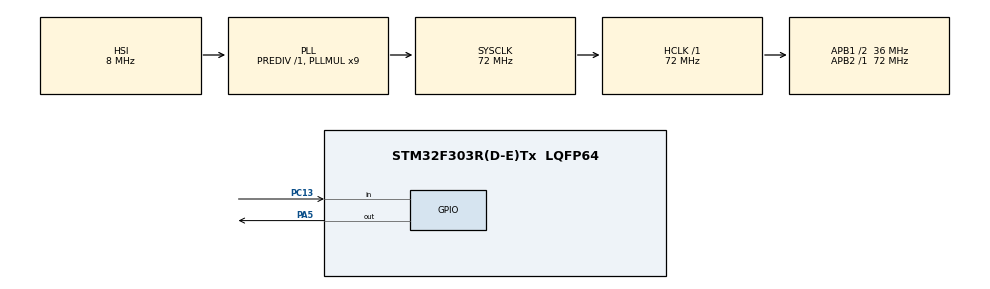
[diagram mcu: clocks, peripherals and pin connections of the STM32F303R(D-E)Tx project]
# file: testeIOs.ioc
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Mcu.Family=STM32F3
Mcu.Name=STM32F303R(D-E)Tx
Mcu.Package=LQFP64
NVIC.PriorityGroup=NVIC_PRIORITYGROUP_4
PA13.Mode=Serial_Wire
PA13.Signal=SYS_JTMS-SWDIO
PA14.Mode=Serial_Wire
PA14.Signal=SYS_JTCK-SWCLK
PA5.GPIO_Speed=GPIO_SPEED_FREQ_HIGH
PA5.PinState=GPIO_PIN_RESET
PA5.Signal=GPIO_Output
PC13.GPIO_PuPd=GPIO_PULLUP
PC13.Signal=GPIO_Input
PF0-OSC_IN.Mode=HSE-External-Oscillator
PF0-OSC_IN.Signal=RCC_OSC_IN
PF1-OSC_OUT.Mode=HSE-External-Oscillator
PF1-OSC_OUT.Signal=RCC_OSC_OUT
ProjectManager.HeapSize=0x200
ProjectManager.StackSize=0x400
ProjectManager.TargetToolchain=STM32CubeIDE
RCC.AHBFreq_Value=72000000
RCC.APB1CLKDivider=RCC_HCLK_DIV2
RCC.APB1Freq_Value=36000000
RCC.APB1TimFreq_Value=72000000
RCC.APB2Freq_Value=72000000
RCC.APB2TimFreq_Value=72000000
RCC.CortexFreq_Value=72000000
RCC.HCLKFreq_Value=72000000
RCC.HSE_VALUE=8000000
RCC.HSI_VALUE=8000000
RCC.PLLMUL=RCC_PLL_MUL9
RCC.SYSCLKFreq_VALUE=72000000
RCC.SYSCLKSourceVirtual=RCC_SYSCLKSOURCE_PLLCLK
RCC.USBFreq_Value=72000000
board=custom

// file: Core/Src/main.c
/* USER CODE BEGIN Header */
/**
  ******************************************************************************
  * @file           : main.c
  * @brief          : Main program body
  ******************************************************************************
  * @attention
  *
  * Copyright (c) 2023 STMicroelectronics.
  * All rights reserved.
  *
  * This software is licensed under terms that can be found in the LICENSE file
  * in the root directory of this software component.
  * If no LICENSE file comes with this software, it is provided AS-IS.
  *
  ******************************************************************************
  */
/* USER CODE END Header */
#include "main.h"

/* USER CODE BEGIN Includes */
#include "teste_IO.h"
/* USER CODE END Includes */

void SystemClock_Config(void);

int main(void)
{

  /* MCU Configuration--------------------------------------------------------*/

  /* Reset of all peripherals, Initializes the Flash interface and the Systick. */
  HAL_Init();

  /* USER CODE BEGIN Init */
  initInput(GPIOC,GPIO_PIN_13);
  initOutput(GPIOA,GPIO_PIN_5);
  /* USER CODE END Init */

  /* Configure the system clock */
  SystemClock_Config();

  /* USER CODE BEGIN 2 */
  	CLKEnable(GPIOA);

  	test_state test;
  	test = input19;
  	//test = output19;
  	//test = input20;
  	//test = output20;

  	switch(test){
  		case input19:
  			inputTC(GPIOC, GPIO_PIN_13, GPIOA, GPIO_PIN_5);
  			break;
  		case output19:
  			outputTC(GPIOA, GPIO_PIN_5, GPIO_PIN_SET);
  			break;
  		case input20:
  			testeInput(GPIOC, GPIO_PIN_13, GPIOA, GPIO_PIN_5);
  			break;
  		case output20:
  			testeOutput(GPIOA, GPIO_PIN_5);
  	}

  /* USER CODE END 2 */

  /* Infinite loop */
  while (1)
  {

  }
}

void SystemClock_Config(void)
{
  RCC_OscInitTypeDef RCC_OscInitStruct = {0};
  RCC_ClkInitTypeDef RCC_ClkInitStruct = {0};

  /** Initializes the RCC Oscillators according to the specified parameters
  * in the RCC_OscInitTypeDef structure.
  */
  RCC_OscInitStruct.OscillatorType = RCC_OSCILLATORTYPE_HSI;
  RCC_OscInitStruct.HSIState = RCC_HSI_ON;
  RCC_OscInitStruct.HSICalibrationValue = RCC_HSICALIBRATION_DEFAULT;
  RCC_OscInitStruct.PLL.PLLState = RCC_PLL_ON;
  RCC_OscInitStruct.PLL.PLLSource = RCC_PLLSOURCE_HSI;
  RCC_OscInitStruct.PLL.PLLMUL = RCC_PLL_MUL9;
  RCC_OscInitStruct.PLL.PREDIV = RCC_PREDIV_DIV1;
  if (HAL_RCC_OscConfig(&RCC_OscInitStruct) != HAL_OK)
  {
    Error_Handler();
  }

  /** Initializes the CPU, AHB and APB buses clocks
  */
  RCC_ClkInitStruct.ClockType = RCC_CLOCKTYPE_HCLK|RCC_CLOCKTYPE_SYSCLK
                              |RCC_CLOCKTYPE_PCLK1|RCC_CLOCKTYPE_PCLK2;
  RCC_ClkInitStruct.SYSCLKSource = RCC_SYSCLKSOURCE_PLLCLK;
  RCC_ClkInitStruct.AHBCLKDivider = RCC_SYSCLK_DIV1;
  RCC_ClkInitStruct.APB1CLKDivider = RCC_HCLK_DIV2;
  RCC_ClkInitStruct.APB2CLKDivider = RCC_HCLK_DIV1;

  if (HAL_RCC_ClockConfig(&RCC_ClkInitStruct, FLASH_LATENCY_2) != HAL_OK)
  {
    Error_Handler();
  }
}

void Error_Handler(void)
{
  __disable_irq();
  while (1)
  {
  }
}
